# S32K312_M7 register map
Vendor: NXP Semiconductors; File version: 1.3
CPU: CM7 r0p1, little endian, MPU, FPU, VTOR, 4 interrupt priority bits
Registers are 32-bit, read-write, reset 0x0 unless marked. A register's access mark holds for its fields unless they carry their own. Offsets are from the block's base; [hi:lo] are bit positions; {n}, {i} and the like mark numbered series.

## ERM
Base 0x4025C000
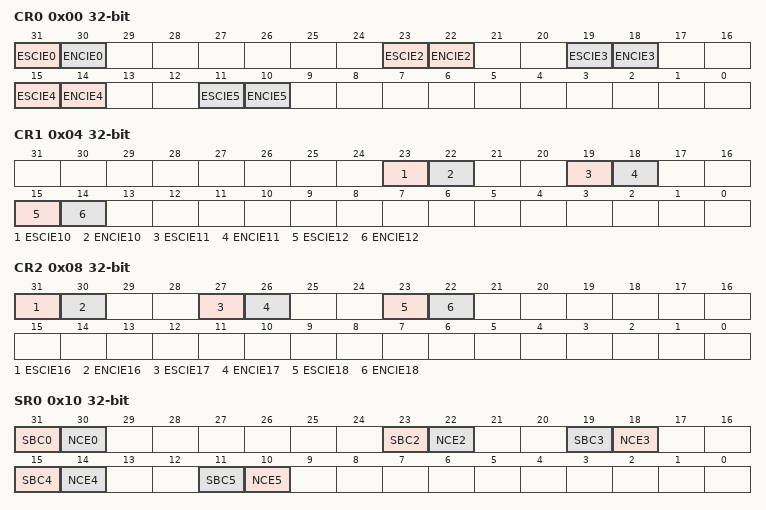
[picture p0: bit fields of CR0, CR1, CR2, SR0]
0x00 CR0 — ERM Configuration Register 0
  [31] ESCIE0
    0=DISABLE (Interrupt notification of Memory 0 single-bit correction events is disabled.); 1=ENABLE (Interrupt notification of Memory 0 single-bit correction events is enabled.)
  [30] ENCIE0
    0=DISABLE (Interrupt notification of Memory 0 non-correctable error events is disabled.); 1=ENABLE (Interrupt notification of Memory 0 non-correctable error events is enabled.)
  [31-4n] ESCIE{n} (n=2..5)
    0=DISABLE (Interrupt notification of Memory {n} single-bit correction events is disabled.); 1=ENABLE (Interrupt notification of Memory {n} single-bit correction events is enabled.)
  [30-4n] ENCIE{n} (n=2..5)
    0=DISABLE (Interrupt notification of Memory {n} non-correctable error events is disabled.); 1=ENABLE (Interrupt notification of Memory {n} non-correctable error events is enabled.)
0x04 CR1 — ERM Configuration Register 1
  [23] ESCIE10
    0=DISABLE (Interrupt notification of Memory 10 single-bit correction events is disabled.); 1=ENABLE (Interrupt notification of Memory 10 single-bit correction events is enabled.)
  [22] ENCIE10
    0=DISABLE (Interrupt notification of Memory 10 non-correctable error events is disabled.); 1=ENABLE (Interrupt notification of Memory 10 non-correctable error events is enabled.)
  [19] ESCIE11
    0=DISABLE (Interrupt notification of Memory 11 single-bit correction events is disabled.); 1=ENABLE (Interrupt notification of Memory 11 single-bit correction events is enabled.)
  [18] ENCIE11
    0=DISABLE (Interrupt notification of Memory 11 non-correctable error events is disabled.); 1=ENABLE (Interrupt notification of Memory 11 non-correctable error events is enabled.)
  [15] ESCIE12
    0=DISABLE (Interrupt notification of Memory 12 single-bit correction events is disabled.); 1=ENABLE (Interrupt notification of Memory 12 single-bit correction events is enabled.)
  [14] ENCIE12
    0=DISABLE (Interrupt notification of Memory 12 non-correctable error events is disabled.); 1=ENABLE (Interrupt notification of Memory 12 non-correctable error events is enabled.)
0x08 CR2 — ERM Configuration Register 2
  [31] ESCIE16
    0=DISABLE (Interrupt notification of Memory 16 single-bit correction events is disabled.); 1=ENABLE (Interrupt notification of Memory 16 single-bit correction events is enabled.)
  [30] ENCIE16
    0=DISABLE (Interrupt notification of Memory 16 non-correctable error events is disabled.); 1=ENABLE (Interrupt notification of Memory 16 non-correctable error events is enabled.)
  [27] ESCIE17
    0=DISABLE (Interrupt notification of Memory 17 single-bit correction events is disabled.); 1=ENABLE (Interrupt notification of Memory 17 single-bit correction events is enabled.)
  [26] ENCIE17
    0=DISABLE (Interrupt notification of Memory 17 non-correctable error events is disabled.); 1=ENABLE (Interrupt notification of Memory 17 non-correctable error events is enabled.)
  [23] ESCIE18
    0=DISABLE (Interrupt notification of Memory 18 single-bit correction events is disabled.); 1=ENABLE (Interrupt notification of Memory 18 single-bit correction events is enabled.)
  [22] ENCIE18
    0=DISABLE (Interrupt notification of Memory 18 non-correctable error events is disabled.); 1=ENABLE (Interrupt notification of Memory 18 non-correctable error events is enabled.)
0x10 SR0 write-1-clears — ERM Status Register 0
  [31] SBC0 write-1-clears
    0=NO_EVENT (No single-bit correction event on Memory 0 detected.); 1=EVENT (Single-bit correction event on Memory 0 detected.)
  [30] NCE0 write-1-clears
    0=NO_ERROR (No non-correctable error event on Memory 0 detected.); 1=ERROR (Non-correctable error event on Memory 0 detected.)
  [23] SBC2 write-1-clears
    0=NO_EVENT (No single-bit correction event on Memory 2 detected.); 1=EVENT (Single-bit correction event on Memory 2 detected.)
  [30-4n] NCE{n} write-1-clears (n=2..5)
    0=NO_ERROR (No non-correctable error event on Memory {n} detected.); 1=ERROR (Non-correctable error event on Memory {n} detected.)
  [19] SBC3 write-1-clears
    0=NO_EVENT (No single-bit correction event on Memory 3 detected.); 1=EVENT (Single-bit correction event on Memory 3 detected.)
  [15] SBC4 write-1-clears
    0=NO_EVENT (No single-bit correction event on Memory 4 detected.); 1=EVENT (Single-bit correction event on Memory 4 detected.)
  [11] SBC5 write-1-clears
    0=NO_EVENT (No single-bit correction event on Memory 5 detected.); 1=CORR_EVENT (Single-bit correction event on Memory 5 detected.)
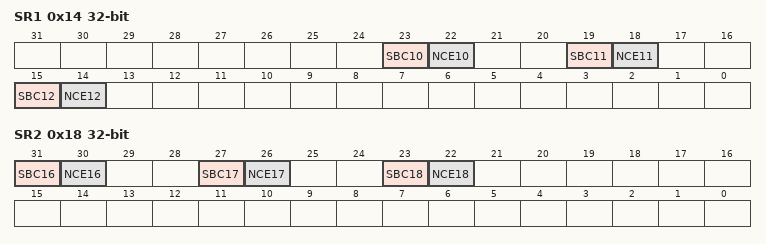
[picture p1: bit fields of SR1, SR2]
0x14 SR1 write-1-clears — ERM Status Register 1
  [23] SBC10 write-1-clears
    0=NO_EVENT (No single-bit correction event on Memory 10 detected.); 1=EVENT (Single-bit correction event on Memory 10 detected.)
  [22] NCE10 write-1-clears
    0=NO_ERROR (No non-correctable error event on Memory 10 detected.); 1=ERROR (Non-correctable error event on Memory 10 detected.)
  [19] SBC11 write-1-clears
    0=NO_EVENT (No single-bit correction event on Memory 11 detected.); 1=EVENT (Single-bit correction event on Memory 11 detected.)
  [18] NCE11 write-1-clears
    0=NO_ERROR (No non-correctable error event on Memory 11 detected.); 1=ERROR (Non-correctable error event on Memory 11 detected.)
  [15] SBC12 write-1-clears
    0=NO_EVENT (No single-bit correction event on Memory 12 detected.); 1=EVENT (Single-bit correction event on Memory 12 detected.)
  [14] NCE12 write-1-clears
    0=NO_ERROR (No non-correctable error event on Memory 12 detected.); 1=ERROR (Non-correctable error event on Memory 12 detected.)
0x18 SR2 write-1-clears — ERM Status Register 2
  [31] SBC16 write-1-clears
    0=NO_EVENT (No single-bit correction event on Memory 16 detected.); 1=EVENT (Single-bit correction event on Memory 16 detected.)
  [30] NCE16 write-1-clears
    0=NO_ERROR (No non-correctable error event on Memory 16 detected.); 1=ERROR (Non-correctable error event on Memory 16 detected.)
  [27] SBC17 write-1-clears
    0=NO_EVENT (No single-bit correction event on Memory 17 detected.); 1=EVENT (Single-bit correction event on Memory 17 detected.)
  [26] NCE17 write-1-clears
    0=NO_ERROR (No non-correctable error event on Memory 17 detected.); 1=ERROR (Non-correctable error event on Memory 17 detected.)
  [23] SBC18 write-1-clears
    0=NO_EVENT (No single-bit correction event on Memory 18 detected.); 1=EVENT (Single-bit correction event on Memory 18 detected.)
  [22] NCE18 write-1-clears
    0=NO_ERROR (No non-correctable error event on Memory 18 detected.); 1=ERROR (Non-correctable error event on Memory 18 detected.)
0x100 EAR0 ro — ERM Memory 0 Error Address Register
  [31:0] EAR
0x104 SYN0 ro — ERM Memory 0 Syndrome Register
  [31:24] SYNDROME
0x108 CORR_ERR_CNT0 — ERM Memory 0 Correctable Error Count Register
  [7:0] COUNT — Memory n Correctable Error Count
{0x108+0x10*i} CORR_ERR_CNT{i} (i=2..5) — ERM Memory {i} Correctable Error Count Register
  [7:0] COUNT — Memory n Correctable Error Count
{0x100+0x10*i} EAR{i} ro (i=10..12) — ERM Memory {i} Error Address Register
  [31:0] EAR
{0x104+0x10*i} SYN{i} ro (i=10..12) — ERM Memory {i} Syndrome Register
  [31:24] SYNDROME
{0x108+0x10*i} CORR_ERR_CNT{i} (i=10..12) — ERM Memory {i} Correctable Error Count Register
  [7:0] COUNT — Memory n Correctable Error Count
{0x100+0x10*i} EAR{i} ro (i=16..18) — ERM Memory {i} Error Address Register
  [31:0] EAR
0x204 SYN16 ro — ERM Memory 16 Syndrome Register
  [31:24] SYNDROME
{0x108+0x10*i} CORR_ERR_CNT{i} (i=16..18) — ERM Memory {i} Correctable Error Count Register
  [7:0] COUNT — Memory n Correctable Error Count
